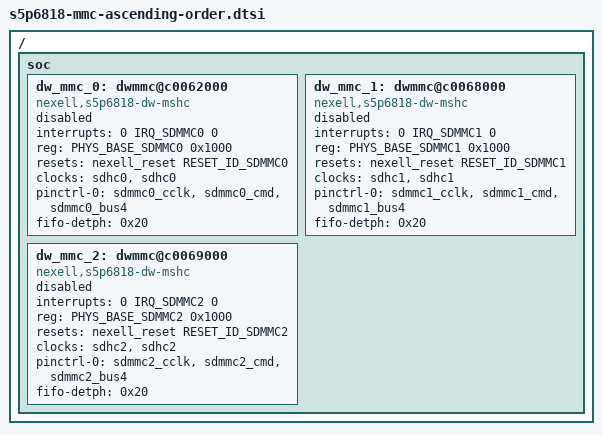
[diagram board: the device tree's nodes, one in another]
#include <dt-bindings/tieoff/s5p6818-tieoff.h>
#include <dt-bindings/soc/s5p6818-base.h>
#include <dt-bindings/reset/nexell,s5p6818-reset.h>
#include <dt-bindings/interrupt-controller/s5p6818-irq.h>
#include <dt-bindings/media/nexell-vip.h>
#include "s5p6818.dtsi"

/ {
	soc {
		/delete-node/	dw_mmc@c0069000;
		/delete-node/	dw_mmc@c0068000;
		/delete-node/	dw_mmc@c0062000;

		dw_mmc_0:dwmmc@c0062000 {
			compatible = "nexell,s5p6818-dw-mshc";
			interrupts = <0 IRQ_SDMMC0 0>;
			#address-cells = <1>;
			#size-cells = <0>;
			reg = <PHYS_BASE_SDMMC0 0x1000>;
			resets  = <&nexell_reset RESET_ID_SDMMC0>;
			reset-names = "dw_mmc-reset";
			clock-names = "biu", "ciu";
			clocks = <&sdhc0>, <&sdhc0>;
			pinctrl-names = "default";
			pinctrl-0 = <&sdmmc0_cclk &sdmmc0_cmd &sdmmc0_bus4>;
			fifo-detph = <0x20>;
			status = "disabled";
		};

		dw_mmc_1:dwmmc@c0068000 {
			compatible = "nexell,s5p6818-dw-mshc";
			interrupts = <0 IRQ_SDMMC1 0>;
			#address-cells = <1>;
			#size-cells = <0>;
			reg = <PHYS_BASE_SDMMC1 0x1000>;
			resets  = <&nexell_reset RESET_ID_SDMMC1>;
			reset-names = "dw_mmc-reset";
			clock-names = "biu","ciu";
			clocks = <&sdhc1>, <&sdhc1>;
			pinctrl-names = "default";
			pinctrl-0 = <&sdmmc1_cclk &sdmmc1_cmd &sdmmc1_bus4>;
			fifo-detph = <0x20>;
			status = "disabled";
		};

		dw_mmc_2:dwmmc@c0069000 {
			compatible = "nexell,s5p6818-dw-mshc";
			interrupts = <0 IRQ_SDMMC2 0>;
			#address-cells = <1>;
			#size-cells = <0>;
			reg = <PHYS_BASE_SDMMC2 0x1000>;
			resets  = <&nexell_reset RESET_ID_SDMMC2>;
			reset-names = "dw_mmc-reset";
			clock-names = "biu","ciu";
			clocks = <&sdhc2>, <&sdhc2>;
			pinctrl-names = "default";
			pinctrl-0 = <&sdmmc2_cclk &sdmmc2_cmd &sdmmc2_bus4>;
			fifo-detph = <0x20>;
			status = "disabled";
		};
	};
};
